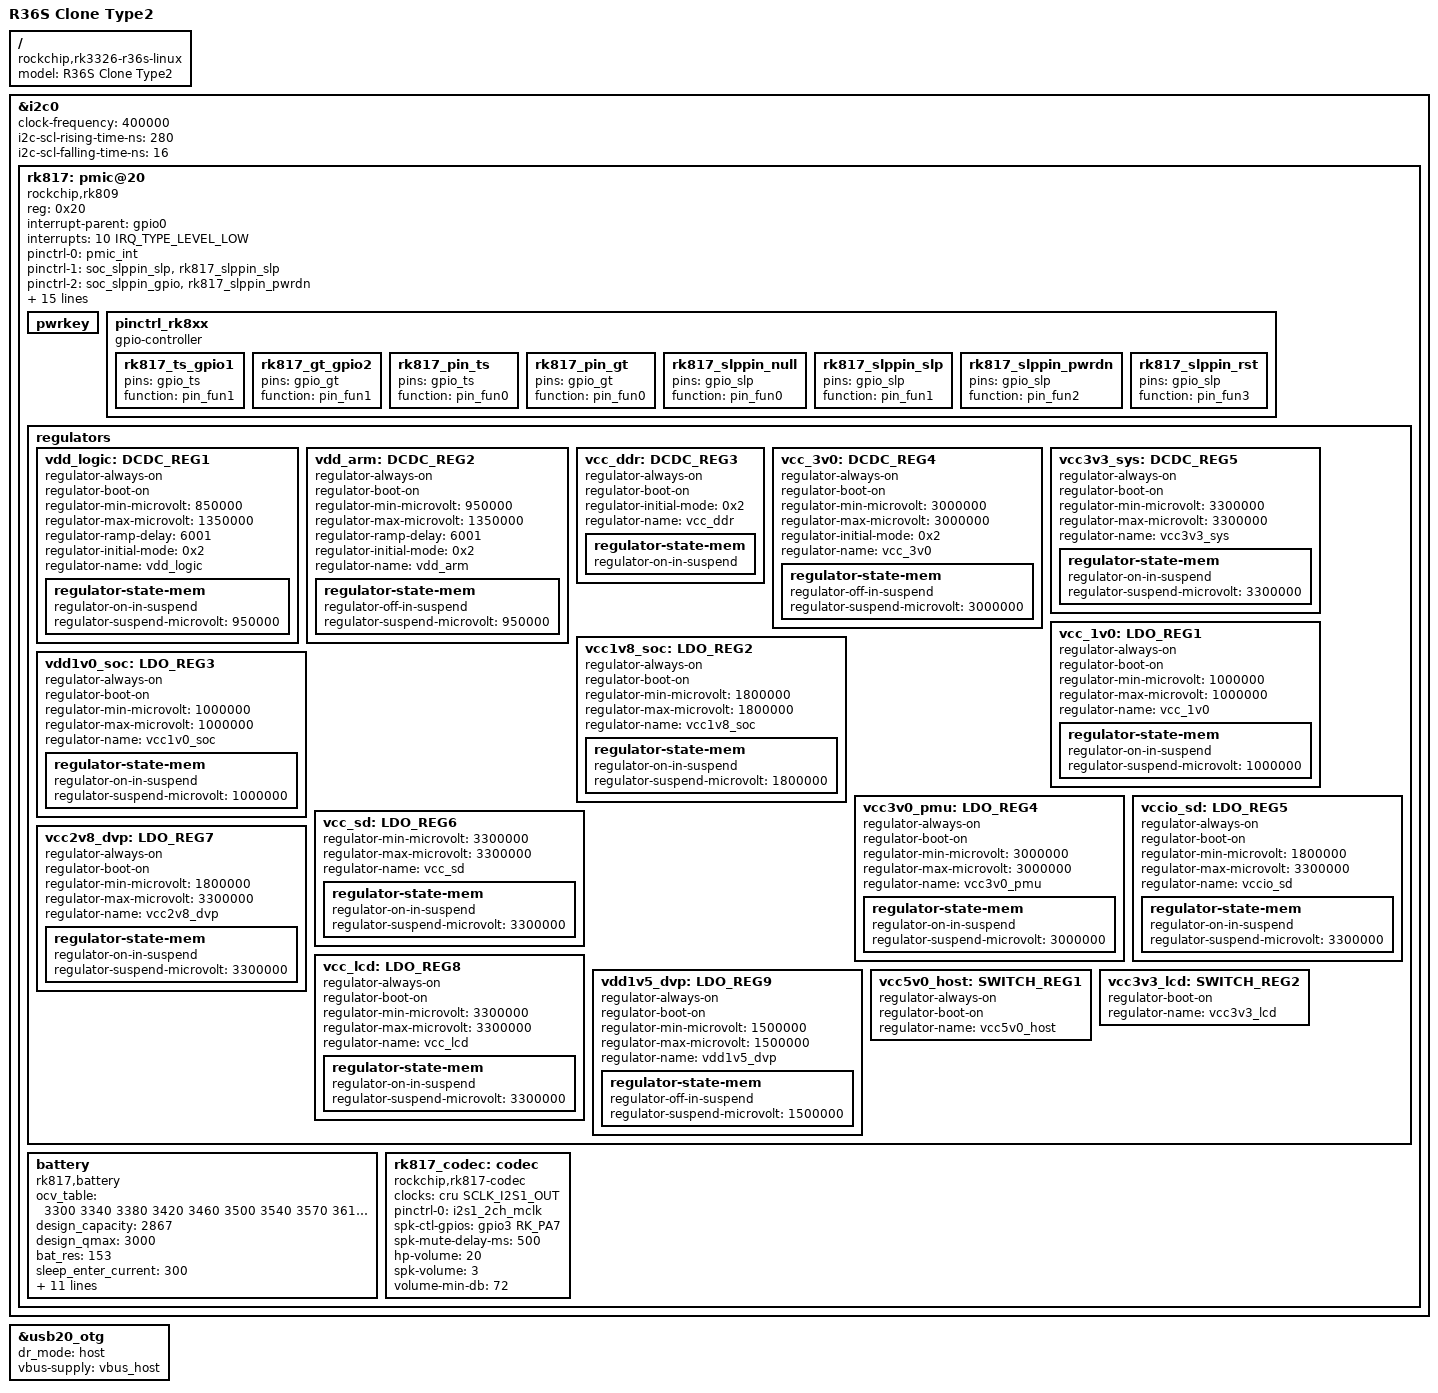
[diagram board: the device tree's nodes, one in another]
// SPDX-License-Identifier: (GPL-2.0+ OR MIT)
/*
* Copyright (c) 2025 kk&lcdyk
*
* R36S Clone掌机 种类2
*
*/

/dts-v1/;

#include "rk3326-r36s-type2-panel1-linux.dts"

/ {
	model = "R36S Clone Type2";
	compatible = "rockchip,rk3326-r36s-linux", "rockchip,rk3326";
};

&i2c0 {
	status = "okay";
	clock-frequency = <400000>;
	i2c-scl-rising-time-ns = <280>;
	i2c-scl-falling-time-ns = <16>;
	
	rk817: pmic@20 {
		compatible = "rockchip,rk809";
		reg = <0x20>;
		interrupt-parent = <&gpio0>;
		interrupts = <10 IRQ_TYPE_LEVEL_LOW>;
		pinctrl-names = "default", "pmic-sleep",
		"pmic-power-off", "pmic-reset";
		pinctrl-0 = <&pmic_int>;
		pinctrl-1 = <&soc_slppin_slp>, <&rk817_slppin_slp>;
		pinctrl-2 = <&soc_slppin_gpio>, <&rk817_slppin_pwrdn>;
		pinctrl-3 = <&soc_slppin_rst>, <&rk817_slppin_rst>;
		rockchip,system-power-controller;
		wakeup-source;
		#clock-cells = <1>;
		clock-output-names = "rk808-clkout1", "rk808-clkout2";
		//fb-inner-reg-idxs = <2>;
		
		/* 1: rst regs (default in codes), 0: rst the pmic */
		pmic-reset-func = <1>;
		
		vcc1-supply = <&vccsys>;
		vcc2-supply = <&vccsys>;
		vcc3-supply = <&vccsys>;
		vcc4-supply = <&vccsys>;
		vcc5-supply = <&vcc3v3_sys>;
		vcc6-supply = <&vcc3v3_sys>;
		vcc7-supply = <&vcc3v3_sys>;
		vcc8-supply = <&vcc3v3_sys>;
		vcc9-supply = <&vccsys>;
		
		pwrkey {
			status = "okay";
		};
		
		pinctrl_rk8xx: pinctrl_rk8xx {
			gpio-controller;
			#gpio-cells = <2>;
			
			rk817_ts_gpio1: rk817_ts_gpio1 {
				pins = "gpio_ts";
				function = "pin_fun1";
				/* output-low; */
				/* input-enable; */
			};
			
			rk817_gt_gpio2: rk817_gt_gpio2 {
				pins = "gpio_gt";
				function = "pin_fun1";
			};
			
			rk817_pin_ts: rk817_pin_ts {
				pins = "gpio_ts";
				function = "pin_fun0";
			};
			
			rk817_pin_gt: rk817_pin_gt {
				pins = "gpio_gt";
				function = "pin_fun0";
			};
			
			rk817_slppin_null: rk817_slppin_null {
				pins = "gpio_slp";
				function = "pin_fun0";
			};
			
			rk817_slppin_slp: rk817_slppin_slp {
				pins = "gpio_slp";
				function = "pin_fun1";
			};
			
			rk817_slppin_pwrdn: rk817_slppin_pwrdn {
				pins = "gpio_slp";
				function = "pin_fun2";
			};
			
			rk817_slppin_rst: rk817_slppin_rst {
				pins = "gpio_slp";
				function = "pin_fun3";
			};
		};
		
		regulators {
			vdd_logic: DCDC_REG1 {
				regulator-always-on;
				regulator-boot-on;
				regulator-min-microvolt = <850000>;
				regulator-max-microvolt = <1350000>;
				regulator-ramp-delay = <6001>;
				regulator-initial-mode = <0x2>;
				regulator-name = "vdd_logic";
				regulator-state-mem {
					regulator-on-in-suspend;
					regulator-suspend-microvolt = <950000>;
				};
			};
			
			vdd_arm: DCDC_REG2 {
				regulator-always-on;
				regulator-boot-on;
				regulator-min-microvolt = <950000>;
				regulator-max-microvolt = <1350000>;
				regulator-ramp-delay = <6001>;
				regulator-initial-mode = <0x2>;
				regulator-name = "vdd_arm";
				regulator-state-mem {
					regulator-off-in-suspend;
					regulator-suspend-microvolt = <950000>;
				};
			};
			
			vcc_ddr: DCDC_REG3 {
				regulator-always-on;
				regulator-boot-on;
				regulator-initial-mode = <0x2>;
				regulator-name = "vcc_ddr";
				regulator-state-mem {
					regulator-on-in-suspend;
				};
			};
			
			vcc_3v0: DCDC_REG4 {
				regulator-always-on;
				regulator-boot-on;
				regulator-min-microvolt = <3000000>;
				regulator-max-microvolt = <3000000>;
				regulator-initial-mode = <0x2>;
				regulator-name = "vcc_3v0";
				regulator-state-mem {
					regulator-off-in-suspend;
					regulator-suspend-microvolt = <3000000>;
				};
			};

			vcc3v3_sys: DCDC_REG5 {
				regulator-always-on;
				regulator-boot-on;
				regulator-min-microvolt = <3300000>;
				regulator-max-microvolt = <3300000>;
				regulator-name = "vcc3v3_sys";

				regulator-state-mem {
					regulator-on-in-suspend;
					regulator-suspend-microvolt = <3300000>;
				};
			};
			
			/* Not Used */
			vcc_1v0: LDO_REG1 {
				regulator-always-on;
				regulator-boot-on;
				regulator-min-microvolt = <1000000>;
				regulator-max-microvolt = <1000000>;
				regulator-name = "vcc_1v0";
				regulator-state-mem {
					regulator-on-in-suspend;
					regulator-suspend-microvolt = <1000000>;
				};
			};
			
			vcc1v8_soc: LDO_REG2 {
				regulator-always-on;
				regulator-boot-on;
				regulator-min-microvolt = <1800000>;
				regulator-max-microvolt = <1800000>;
				
				regulator-name = "vcc1v8_soc";
				regulator-state-mem {
					regulator-on-in-suspend;
					regulator-suspend-microvolt = <1800000>;
				};
			};
			
			vdd1v0_soc: LDO_REG3 {
				regulator-always-on;
				regulator-boot-on;
				regulator-min-microvolt = <1000000>;
				regulator-max-microvolt = <1000000>;
				
				regulator-name = "vcc1v0_soc";
				regulator-state-mem {
					regulator-on-in-suspend;
					regulator-suspend-microvolt = <1000000>;
				};
			};
			
			vcc3v0_pmu: LDO_REG4 {
				regulator-always-on;
				regulator-boot-on;
				regulator-min-microvolt = <3000000>;
				regulator-max-microvolt = <3000000>;
				
				regulator-name = "vcc3v0_pmu";
				regulator-state-mem {
					regulator-on-in-suspend;
					regulator-suspend-microvolt = <3000000>;
				};
			};
			
			vccio_sd: LDO_REG5 {
				regulator-always-on;
				regulator-boot-on;
				regulator-min-microvolt = <1800000>;
				regulator-max-microvolt = <3300000>;
				
				regulator-name = "vccio_sd";
				regulator-state-mem {
					regulator-on-in-suspend;
					regulator-suspend-microvolt = <3300000>;
				};
			};
			
			vcc_sd: LDO_REG6 {
				regulator-min-microvolt = <3300000>;
				regulator-max-microvolt = <3300000>;
				
				regulator-name = "vcc_sd";
				regulator-state-mem {
					regulator-on-in-suspend;
					regulator-suspend-microvolt = <3300000>;
				};
			};
			
			/* Rev 0.2 LCD Backlight Power */
			vcc2v8_dvp: LDO_REG7 {
				regulator-always-on;
				regulator-boot-on;
				regulator-min-microvolt = <1800000>;
				regulator-max-microvolt = <3300000>;
				
				regulator-name = "vcc2v8_dvp";
				regulator-state-mem {
					regulator-on-in-suspend;
					regulator-suspend-microvolt = <3300000>;
				};
			};
			
			/* Rev 0.2 LCD IO Power */
			vcc_lcd: LDO_REG8 {
				regulator-always-on;
				regulator-boot-on;
				regulator-min-microvolt = <3300000>;
				regulator-max-microvolt = <3300000>;
				
				regulator-name = "vcc_lcd";
				regulator-state-mem {
					regulator-on-in-suspend;
					regulator-suspend-microvolt = <3300000>;
				};
			};
			
			vdd1v5_dvp: LDO_REG9 {
				regulator-always-on;
				regulator-boot-on;
				regulator-min-microvolt = <1500000>;
				regulator-max-microvolt = <1500000>;
				
				regulator-name = "vdd1v5_dvp";
				regulator-state-mem {
					regulator-off-in-suspend;
					regulator-suspend-microvolt = <1500000>;
				};
			};
			
			vcc5v0_host: SWITCH_REG1 {
				regulator-always-on;
				regulator-boot-on;
				regulator-name = "vcc5v0_host";
			};

			vcc3v3_lcd: SWITCH_REG2 {
				regulator-boot-on;
				regulator-name = "vcc3v3_lcd";
			};
		};
		
		battery {
			compatible = "rk817,battery", "rk817_fg";
			ocv_table = <
			3300 3340 3380 3420 3460 3500 3540
			3570 3610 3650 3690 3720 3750 3790
			3830 3870 3910 3940 3967 4001 4046
			>;
			design_capacity = <2867>;
			design_qmax = <3000>;
			bat_res = <153>;
			sleep_enter_current = <300>;
			sleep_exit_current = <300>;
			sleep_filter_current = <100>;
			power_off_thresd = <3300>;
			zero_algorithm_vol = <3850>;
			max_soc_offset = <60>;
			monitor_sec = <5>;
			sample_res = <10>;
			virtual_power = <0>;
			power_dc2otg = <0>;
			bat_res_up = <140>;
			bat_res_down = <20>;
		};
		
		rk817_codec: codec {
			#sound-dai-cells = <0>;
			compatible = "rockchip,rk817-codec";
			clocks = <&cru SCLK_I2S1_OUT>;
			clock-names = "mclk";
			pinctrl-names = "default";
			pinctrl-0 = <&i2s1_2ch_mclk>;
			spk-ctl-gpios = <&gpio3 RK_PA7 GPIO_ACTIVE_HIGH>;
			spk-mute-delay-ms = <500>;
			hp-volume = <20>;
			spk-volume = <3>;
			volume-min-db = <72>;  /* -90*0.5 = -45 */
			status = "okay";
		};
	};
};

&usb20_otg {
	dr_mode = "host";
	vbus-supply = <&vbus_host>;
	status = "okay";
};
